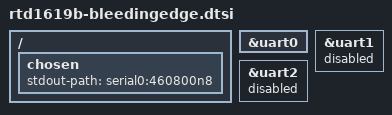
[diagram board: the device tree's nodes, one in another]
// SPDX-License-Identifier: (GPL-2.0-or-later OR BSD-2-Clause)
/*
 * Copyright (c) 2020 Realtek Semiconductor Corp.
 */

/dts-v1/;

#include <dt-bindings/thermal/thermal.h>
#include "rtd16xxb.dtsi"

/ {
	chosen {
		stdout-path = "serial0:460800n8";
	};
};

/* debug console (J1) */
&uart0 {
	status = "okay";
};

/* M.2 slot (CON2) */
&uart1 {
	status = "disabled";
};

&uart2 {
	status = "disabled";
};
